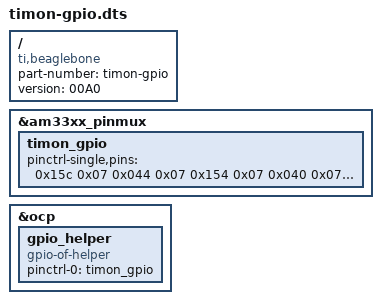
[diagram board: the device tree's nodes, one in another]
/**
 * Device tree overlay describing how to 
 */

/* OUTPUT GPIO(mode7) 0x07 pulldown, 0x17 pullup, 0x?f no pullup/down */
/* INPUT GPIO(mode7) 0x27 pulldown, 0x37 pullup, 0x?f no pullup/down */

/dts-v1/;
/plugin/;

/{
  compatible = "ti,beaglebone", "ti,beaglebone-black";
  part-number = "timon-gpio";
  version = "00A0";

  fragment@0 {
    target = <&am33xx_pinmux>;
    __overlay__ {
      timon_gpio: timon_gpio {
        pinctrl-single,pins = <
	  // Four output pins for H-Bridge direction
          0x15c 0x07 // P9_17 $87 GPIO0_5=5
          0x044 0x07 // P9_23 $17 GPIO1_17=49 
          0x154 0x07 // P9_21 $85 GPIO0_3=3
          0x040 0x07 // P9_15 $16 GPIO1_16=48 
	  // Two input pins for reading back buttons
          0x158 0x27 // P9_18 $86 GPIO0_4=4
          0x184 0x27 // P9_24 $97 GPIO0_15=15
        >;
      };
    };
  };

  fragment@1 {
    target = <&ocp>;
    __overlay__ {
      gpio_helper {
        compatible = "gpio-of-helper";
        status = "okay";
        pinctrl-names = "default";
        pinctrl-0 = <&timon_gpio>;
      };
    };
  };

};
